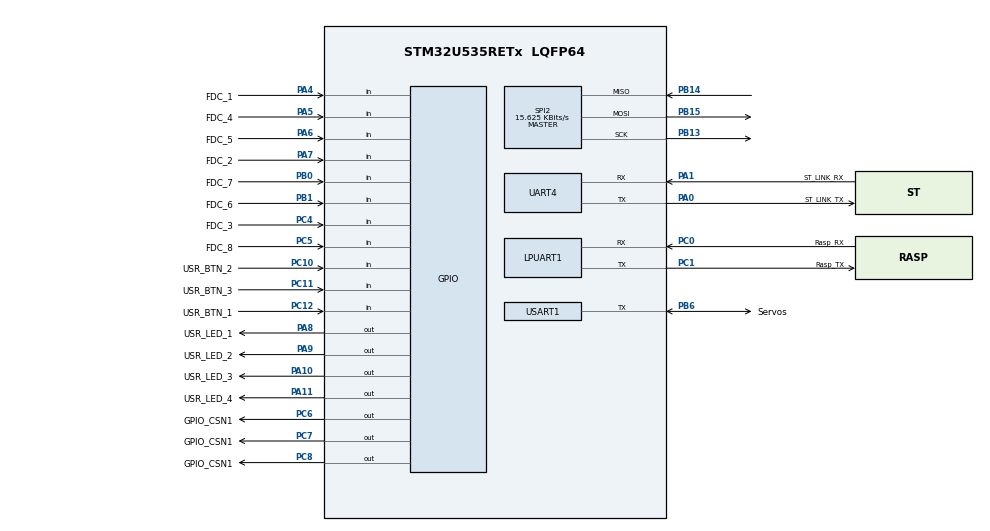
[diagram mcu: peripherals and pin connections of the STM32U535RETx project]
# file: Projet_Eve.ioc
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CORTEX_M33_NS.userName=CORTEX_M33
Mcu.Family=STM32U5
Mcu.Name=STM32U535RETx
Mcu.Package=LQFP64
NVIC.PriorityGroup=NVIC_PRIORITYGROUP_4
PA0.GPIO_Label=ST_LINK_TX
PA0.Mode=Asynchronous
PA0.Signal=UART4_TX
PA1.GPIO_Label=ST_LINK_RX
PA1.Mode=Asynchronous
PA1.Signal=UART4_RX
PA10.GPIO_Label=USR_LED_3
PA10.Signal=GPIO_Output
PA11.GPIO_Label=USR_LED_4
PA11.Signal=GPIO_Output
PA13\ (JTMS/SWDIO).Signal=DEBUG_JTMS-SWDIO
PA14\ (JTCK/SWCLK).Signal=DEBUG_JTCK-SWCLK
PA4.GPIO_Label=FDC_1
PA4.Signal=GPIO_Input
PA5.GPIO_Label=FDC_4
PA5.Signal=GPIO_Input
PA6.GPIO_Label=FDC_5
PA6.Signal=GPIO_Input
PA7.GPIO_Label=FDC_2
PA7.Signal=GPIO_Input
PA8.GPIO_Label=USR_LED_1
PA8.Signal=GPIO_Output
PA9.GPIO_Label=USR_LED_2
PA9.Signal=GPIO_Output
PB0.GPIO_Label=FDC_7
PB0.Signal=GPIO_Input
PB1.GPIO_Label=FDC_6
PB1.Signal=GPIO_Input
PB13.Mode=Full_Duplex_Master
PB13.Signal=SPI2_SCK
PB14.Mode=Full_Duplex_Master
PB14.Signal=SPI2_MISO
PB15.Mode=Full_Duplex_Master
PB15.Signal=SPI2_MOSI
PB3\ (JTDO/TRACESWO).Signal=DEBUG_JTDO-SWO
PB6.GPIO_Label=Servos
PB6.GPIO_ModeDefaultOD=GPIO_MODE_AF_OD
PB6.GPIO_PuPd=GPIO_PULLUP
PB6.GPIO_Speed=GPIO_SPEED_FREQ_VERY_HIGH
PB6.Mode=Half_duplex(single_wire_mode)
PB6.Signal=USART1_TX
PC0.GPIO_Label=Rasp_RX
PC0.Mode=Asynchronous
PC0.Signal=LPUART1_RX
PC1.GPIO_Label=Rasp_TX
PC1.Mode=Asynchronous
PC1.Signal=LPUART1_TX
PC10.GPIO_Label=USR_BTN_2
PC10.Signal=GPIO_Input
PC11.GPIO_Label=USR_BTN_3
PC11.Signal=GPIO_Input
PC12.GPIO_Label=USR_BTN_1
PC12.Signal=GPIO_Input
PC4.GPIO_Label=FDC_3
PC4.Signal=GPIO_Input
PC5.GPIO_Label=FDC_8
PC5.Signal=GPIO_Input
PC6.GPIO_Label=GPIO_CSN1
PC6.Signal=GPIO_Output
PC7.GPIO_Label=GPIO_CSN1
PC7.Signal=GPIO_Output
PC8.GPIO_Label=GPIO_CSN1
PC8.Signal=GPIO_Output
PH0-OSC_IN\ (PH0).Mode=HSE-External-Oscillator
PH0-OSC_IN\ (PH0).Signal=RCC_OSC_IN
PH1-OSC_OUT\ (PH1).Mode=HSE-External-Oscillator
PH1-OSC_OUT\ (PH1).Signal=RCC_OSC_OUT
ProjectManager.HeapSize=0x200
ProjectManager.StackSize=0x400
ProjectManager.TargetToolchain=STM32CubeIDE
RCC.ADCFreq_Value=16000000
RCC.DACCLockSelectionVirtual=RCC_DAC1CLKSOURCE_LSI
RCC.DACCLockSelectionVirtualString=RCC_DAC1CLKSOURCE_LSI
RCC.EPOD_VALUE=4000000
RCC.HSE_VALUE=16000000
RCC.HSI48_VALUE=48000000
RCC.HSI_VALUE=16000000
RCC.LSE_VALUE=32768
RCC.LSIDIV_VALUE=32000
RCC.MSI_VALUE=4000000
RCC.USBFreq_Value=48000000
RCC.VCOOutputFreq_Value=516000000
SPI2.BaudRatePrescaler=SPI_BAUDRATEPRESCALER_256
SPI2.CalculateBaudRate=15.625 KBits/s
SPI2.DataSize=SPI_DATASIZE_8BIT
SPI2.Direction=SPI_DIRECTION_2LINES
SPI2.Mode=SPI_MODE_MASTER
SPI2.VirtualType=VM_MASTER
USART1.BaudRate=57600
USART1.VirtualMode-Half_duplex(single_wire_mode)=VM_ASYNC
VP_ICACHE_VS_ICACHE.Mode=DirectMappedCache
VP_LPBAMQUEUE_VS_QUEUE.Mode=QUEUEMODE
VP_LPBAM_VS_SIG1.Mode=SmartRun
VP_LPBAM_VS_SIG4.Mode=LPDMA1
VP_MEMORYMAP_VS_MEMORYMAP.Mode=CurAppReg
VP_PWR_VS_SECSignals.Mode=Security/Privilege
board=custom

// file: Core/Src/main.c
/* USER CODE BEGIN Header */
/**
  ******************************************************************************
  * @file           : main.c
  * @brief          : Main program body
  ******************************************************************************
  * @attention
  *
  * Copyright (c) 2024 STMicroelectronics.
  * All rights reserved.
  *
  * This software is licensed under terms that can be found in the LICENSE file
  * in the root directory of this software component.
  * If no LICENSE file comes with this software, it is provided AS-IS.
  *
  ******************************************************************************
  */
/* USER CODE END Header */
#include "main.h"
#include "icache.h"
#include "usart.h"
#include "memorymap.h"
#include "spi.h"
#include "gpio.h"

/* USER CODE BEGIN Includes */
#include <stdio.h>
#include <string.h>
#include <stdint.h>
#include "dyn2.h"
#include "constants.h"

/* USER CODE END Includes */

void SystemClock_Config(void);

int main(void)
{

  /* MCU Configuration--------------------------------------------------------*/

  /* Reset of all peripherals, Initializes the Flash interface and the Systick. */
  HAL_Init();

  /* Configure the system clock */
  SystemClock_Config();

  /* Initialize all configured peripherals */
  MX_GPIO_Init();
  MX_USART1_UART_Init();
  MX_ICACHE_Init();
  MX_LPUART1_UART_Init();
  MX_UART4_Init();
  MX_SPI2_Init();
  /* USER CODE BEGIN 2 */
  uint8_t ID = 0x01;
  dyn2_torque(ID,TORQUE_ON);

  /* USER CODE END 2 */

  /* Infinite loop */
  /* USER CODE BEGIN WHILE */
  while (1)
  {
	  dyn2_led(ID,LED_ON);
	  dyn2_position(ID,180);
	  HAL_Delay(1000);
	  dyn2_led(ID,LED_OFF);
	  dyn2_position(ID,0);

	  HAL_Delay(1000);
    /* USER CODE END WHILE */

  }
}

void SystemClock_Config(void)
{
  RCC_OscInitTypeDef RCC_OscInitStruct = {0};
  RCC_ClkInitTypeDef RCC_ClkInitStruct = {0};

  /** Configure the main internal regulator output voltage
  */
  if (HAL_PWREx_ControlVoltageScaling(PWR_REGULATOR_VOLTAGE_SCALE4) != HAL_OK)
  {
    Error_Handler();
  }

  /** Initializes the CPU, AHB and APB buses clocks
  */
  RCC_OscInitStruct.OscillatorType = RCC_OSCILLATORTYPE_MSI;
  RCC_OscInitStruct.MSIState = RCC_MSI_ON;
  RCC_OscInitStruct.MSICalibrationValue = RCC_MSICALIBRATION_DEFAULT;
  RCC_OscInitStruct.MSIClockRange = RCC_MSIRANGE_4;
  RCC_OscInitStruct.PLL.PLLState = RCC_PLL_NONE;
  if (HAL_RCC_OscConfig(&RCC_OscInitStruct) != HAL_OK)
  {
    Error_Handler();
  }

  /** Initializes the CPU, AHB and APB buses clocks
  */
  RCC_ClkInitStruct.ClockType = RCC_CLOCKTYPE_HCLK|RCC_CLOCKTYPE_SYSCLK
                              |RCC_CLOCKTYPE_PCLK1|RCC_CLOCKTYPE_PCLK2
                              |RCC_CLOCKTYPE_PCLK3;
  RCC_ClkInitStruct.SYSCLKSource = RCC_SYSCLKSOURCE_MSI;
  RCC_ClkInitStruct.AHBCLKDivider = RCC_SYSCLK_DIV1;
  RCC_ClkInitStruct.APB1CLKDivider = RCC_HCLK_DIV1;
  RCC_ClkInitStruct.APB2CLKDivider = RCC_HCLK_DIV1;
  RCC_ClkInitStruct.APB3CLKDivider = RCC_HCLK_DIV1;

  if (HAL_RCC_ClockConfig(&RCC_ClkInitStruct, FLASH_LATENCY_0) != HAL_OK)
  {
    Error_Handler();
  }
}

void Error_Handler(void)
{
  __disable_irq();
  while (1)
  {
  }
}
